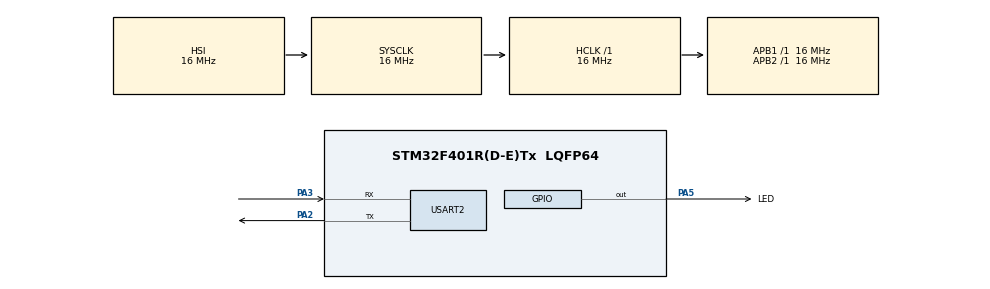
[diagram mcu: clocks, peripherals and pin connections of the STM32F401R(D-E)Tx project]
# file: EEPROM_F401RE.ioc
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Mcu.Family=STM32F4
Mcu.Name=STM32F401R(D-E)Tx
Mcu.Package=LQFP64
NVIC.PriorityGroup=NVIC_PRIORITYGROUP_4
PA2.Mode=Asynchronous
PA2.Signal=USART2_TX
PA3.Mode=Asynchronous
PA3.Signal=USART2_RX
PA5.GPIO_Label=LED
PA5.Signal=GPIO_Output
ProjectManager.HeapSize=0x200
ProjectManager.StackSize=0x400
ProjectManager.TargetToolchain=STM32CubeIDE
RCC.AHBFreq_Value=16000000
RCC.APB1Freq_Value=16000000
RCC.APB2Freq_Value=16000000
RCC.CortexFreq_Value=16000000
RCC.HSE_VALUE=25000000
RCC.HSI_VALUE=16000000
RCC.LSE_VALUE=32768
RCC.SYSCLKFreq_VALUE=16000000
RCC.VCOOutputFreq_Value=192000000
USART2.VirtualMode=VM_ASYNC
board=custom

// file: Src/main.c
/* USER CODE BEGIN Header */
/**
  ******************************************************************************
  * @file           : main.c
  * @brief          : Main program body
  ******************************************************************************
  * @attention
  *
  * <h2><center>&copy; Copyright (c) 2019 STMicroelectronics.
  * All rights reserved.</center></h2>
  *
  * This software component is licensed by ST under BSD 3-Clause license,
  * the "License"; You may not use this file except in compliance with the
  * License. You may obtain a copy of the License at:
  *                        opensource.org/licenses/BSD-3-Clause
  *
  ******************************************************************************
 *  Created on: 21.07.2019
 *      Author: Mateusz Salamon
 *		mateusz@msalamon.pl
 *
 *      Website: https://msalamon.pl/w-stm32-nie-ma-eepromu-ale-na-szczescie-jest-emulacja-eeprom-w-oparciu-o-f1-f4/
 *      GitHub:  https://github.com/lamik/EEPROM-emulation-STM32F4-HAL
  */
/* USER CODE END Header */

#include "main.h"

/* USER CODE BEGIN Includes */
#include "eeprom.h"
/* USER CODE END Includes */

UART_HandleTypeDef huart2;

/* USER CODE BEGIN PV */

/* Virtual address defined by the user: 0xFFFF value is prohibited */
uint16_t VirtAddVarTab[NB_OF_VAR];
uint16_t VarDataTab[NB_OF_VAR] = {'M', 'a', 't', 'e', 'u', 's', 'z', ' ', 'S', 'a', 'l', 'a', 'm', 'o', 'n',
									' ', 'm', 's', 'a', 'l', 'a', 'm', 'o', 'n', '.', 'p', 'l'};
uint8_t VarDataTabRead[NB_OF_VAR];
uint16_t VarIndex,VarDataTmp = 0;
/* USER CODE END PV */

void SystemClock_Config(void);
static void MX_GPIO_Init(void);
static void MX_USART2_UART_Init(void);

int main(void)
{

  /* MCU Configuration--------------------------------------------------------*/

  /* Reset of all peripherals, Initializes the Flash interface and the Systick. */
  HAL_Init();

  /* Configure the system clock */
  SystemClock_Config();

  /* Initialize all configured peripherals */
  MX_GPIO_Init();
  MX_USART2_UART_Init();
  /* USER CODE BEGIN 2 */

  /* Unlock the Flash Program Erase controller */
  HAL_FLASH_Unlock();

  HAL_GPIO_WritePin(LED_GPIO_Port, LED_Pin, GPIO_PIN_SET);

  /* EEPROM Init */
  if( EE_Init() != EE_OK)
  {
    Error_Handler();
  }

  // Fill EEPROM variables addresses
  for(VarIndex = 1; VarIndex <= NB_OF_VAR; VarIndex++)
  {
	  VirtAddVarTab[VarIndex-1] = VarIndex;
  }

  // Store Values in EEPROM emulation
  HAL_UART_Transmit(&huart2, "Store values\n\r", 14, 100);

  HAL_GPIO_WritePin(LED_GPIO_Port, LED_Pin, GPIO_PIN_RESET);
	for (VarIndex = 0; VarIndex < NB_OF_VAR; VarIndex++)
	{
	  /* Sequence 1 */
	  if((EE_WriteVariable(VirtAddVarTab[VarIndex],  VarDataTab[VarIndex])) != HAL_OK)
	  {
		Error_Handler();
	  }
	}
	HAL_GPIO_WritePin(LED_GPIO_Port, LED_Pin, GPIO_PIN_SET);

  // Read values
  HAL_UART_Transmit(&huart2, "Read values\n\r", 13, 100);
  HAL_GPIO_WritePin(LED_GPIO_Port, LED_Pin, GPIO_PIN_RESET);
  for (VarIndex = 0; VarIndex < NB_OF_VAR; VarIndex++)
  {
	  if((EE_ReadVariable(VirtAddVarTab[VarIndex],  &VarDataTabRead[VarIndex])) != HAL_OK)
	  {
		  Error_Handler();
	  }
  }
  HAL_GPIO_WritePin(LED_GPIO_Port, LED_Pin, GPIO_PIN_SET);

  HAL_UART_Transmit(&huart2, "Read table: ", 12, 100);
  HAL_UART_Transmit(&huart2, VarDataTabRead, NB_OF_VAR, 1000);
  HAL_UART_Transmit(&huart2, "\n\r", 2, 100);

  // Store revert Values in EEPROM emulation
  HAL_UART_Transmit(&huart2, "\n\r", 2, 100);
  HAL_UART_Transmit(&huart2, "Store revert values\n\r", 21, 100);

  HAL_GPIO_WritePin(LED_GPIO_Port, LED_Pin, GPIO_PIN_RESET);
	for (VarIndex = 0; VarIndex < NB_OF_VAR; VarIndex++)
	{
	  /* Sequence 1 */
	  if((EE_WriteVariable(VirtAddVarTab[VarIndex],  VarDataTab[NB_OF_VAR-VarIndex-1])) != HAL_OK)
	  {
		Error_Handler();
	  }
	}
	HAL_GPIO_WritePin(LED_GPIO_Port, LED_Pin, GPIO_PIN_SET);

  // Read values
  HAL_UART_Transmit(&huart2, "Read revert values\n\r", 20, 100);
  HAL_GPIO_WritePin(LED_GPIO_Port, LED_Pin, GPIO_PIN_RESET);
  for (VarIndex = 0; VarIndex < NB_OF_VAR; VarIndex++)
  {
	  if((EE_ReadVariable(VirtAddVarTab[VarIndex],  &VarDataTabRead[VarIndex])) != HAL_OK)
	  {
		  Error_Handler();
	  }
  }
  HAL_GPIO_WritePin(LED_GPIO_Port, LED_Pin, GPIO_PIN_SET);

  HAL_UART_Transmit(&huart2, "Read revert table: ", 19, 100);
  HAL_UART_Transmit(&huart2, VarDataTabRead, NB_OF_VAR, 1000);
  HAL_UART_Transmit(&huart2, "\n\r", 2, 100);

  // Store Values in EEPROM emulation
  HAL_UART_Transmit(&huart2, "\n\r", 2, 100);
  HAL_UART_Transmit(&huart2, "Store values\n\r", 14, 100);

  HAL_GPIO_WritePin(LED_GPIO_Port, LED_Pin, GPIO_PIN_RESET);
	for (VarIndex = 0; VarIndex < NB_OF_VAR; VarIndex++)
	{
	  /* Sequence 1 */
	  if((EE_WriteVariable(VirtAddVarTab[VarIndex],  VarDataTab[VarIndex])) != HAL_OK)
	  {
		Error_Handler();
	  }
	}
	HAL_GPIO_WritePin(LED_GPIO_Port, LED_Pin, GPIO_PIN_SET);

  // Read values
  HAL_UART_Transmit(&huart2, "Read values\n\r", 13, 100);
  HAL_GPIO_WritePin(LED_GPIO_Port, LED_Pin, GPIO_PIN_RESET);
  for (VarIndex = 0; VarIndex < NB_OF_VAR; VarIndex++)
  {
	  if((EE_ReadVariable(VirtAddVarTab[VarIndex],  &VarDataTabRead[VarIndex])) != HAL_OK)
	  {
		  Error_Handler();
	  }
  }
  HAL_GPIO_WritePin(LED_GPIO_Port, LED_Pin, GPIO_PIN_SET);

  HAL_UART_Transmit(&huart2, "Read table: ", 12, 100);
  HAL_UART_Transmit(&huart2, VarDataTabRead, NB_OF_VAR, 1000);
  HAL_UART_Transmit(&huart2, "\n\r", 2, 100);
  /* USER CODE END 2 */

  /* Infinite loop */
  while (1)
  {

  }
}

void SystemClock_Config(void)
{
  RCC_OscInitTypeDef RCC_OscInitStruct = {0};
  RCC_ClkInitTypeDef RCC_ClkInitStruct = {0};

  /** Configure the main internal regulator output voltage
  */
  __HAL_RCC_PWR_CLK_ENABLE();
  __HAL_PWR_VOLTAGESCALING_CONFIG(PWR_REGULATOR_VOLTAGE_SCALE2);
  /** Initializes the CPU, AHB and APB busses clocks
  */
  RCC_OscInitStruct.OscillatorType = RCC_OSCILLATORTYPE_HSI;
  RCC_OscInitStruct.HSIState = RCC_HSI_ON;
  RCC_OscInitStruct.HSICalibrationValue = RCC_HSICALIBRATION_DEFAULT;
  RCC_OscInitStruct.PLL.PLLState = RCC_PLL_NONE;
  if (HAL_RCC_OscConfig(&RCC_OscInitStruct) != HAL_OK)
  {
    Error_Handler();
  }
  /** Initializes the CPU, AHB and APB busses clocks
  */
  RCC_ClkInitStruct.ClockType = RCC_CLOCKTYPE_HCLK|RCC_CLOCKTYPE_SYSCLK
                              |RCC_CLOCKTYPE_PCLK1|RCC_CLOCKTYPE_PCLK2;
  RCC_ClkInitStruct.SYSCLKSource = RCC_SYSCLKSOURCE_HSI;
  RCC_ClkInitStruct.AHBCLKDivider = RCC_SYSCLK_DIV1;
  RCC_ClkInitStruct.APB1CLKDivider = RCC_HCLK_DIV1;
  RCC_ClkInitStruct.APB2CLKDivider = RCC_HCLK_DIV1;

  if (HAL_RCC_ClockConfig(&RCC_ClkInitStruct, FLASH_LATENCY_0) != HAL_OK)
  {
    Error_Handler();
  }
}

static void MX_USART2_UART_Init(void)
{

  huart2.Instance = USART2;
  huart2.Init.BaudRate = 115200;
  huart2.Init.WordLength = UART_WORDLENGTH_8B;
  huart2.Init.StopBits = UART_STOPBITS_1;
  huart2.Init.Parity = UART_PARITY_NONE;
  huart2.Init.Mode = UART_MODE_TX_RX;
  huart2.Init.HwFlowCtl = UART_HWCONTROL_NONE;
  huart2.Init.OverSampling = UART_OVERSAMPLING_16;
  if (HAL_UART_Init(&huart2) != HAL_OK)
  {
    Error_Handler();
  }

}

static void MX_GPIO_Init(void)
{
  GPIO_InitTypeDef GPIO_InitStruct = {0};

  /* GPIO Ports Clock Enable */
  __HAL_RCC_GPIOA_CLK_ENABLE();

  /*Configure GPIO pin Output Level */
  HAL_GPIO_WritePin(LED_GPIO_Port, LED_Pin, GPIO_PIN_RESET);

  /*Configure GPIO pin : LED_Pin */
  GPIO_InitStruct.Pin = LED_Pin;
  GPIO_InitStruct.Mode = GPIO_MODE_OUTPUT_PP;
  GPIO_InitStruct.Pull = GPIO_NOPULL;
  GPIO_InitStruct.Speed = GPIO_SPEED_FREQ_LOW;
  HAL_GPIO_Init(LED_GPIO_Port, &GPIO_InitStruct);

}

void Error_Handler(void)
{
  /* USER CODE BEGIN Error_Handler_Debug */
  /* User can add his own implementation to report the HAL error return state */
	  while(1)
	  {
	    /* Toggle LED2 fast */
	    HAL_GPIO_TogglePin(LED_GPIO_Port, LED_Pin);
	    HAL_Delay(40);
	  }
  /* USER CODE END Error_Handler_Debug */
}

/************************ (C) COPYRIGHT STMicroelectronics *****END OF FILE****/
